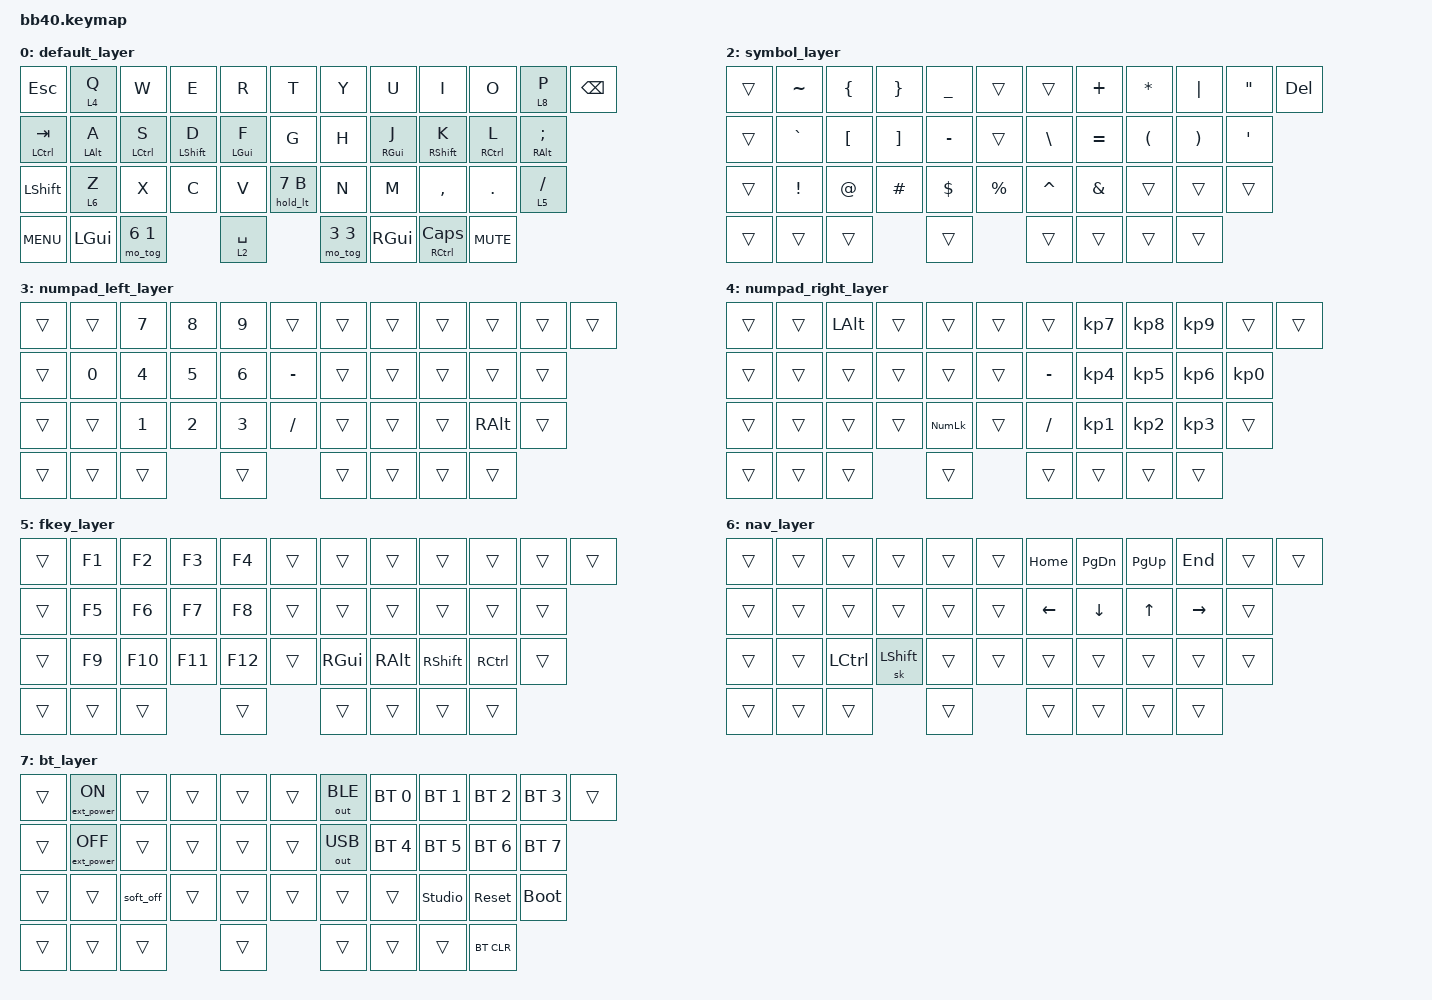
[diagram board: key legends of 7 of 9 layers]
/*
 * Copyright (c) 2025 The ZMK Contributors
 *
 * SPDX-License-Identifier: MIT
 */

#include <behaviors.dtsi>
#include <dt-bindings/zmk/bt.h>
#include <dt-bindings/zmk/ext_power.h>
#include <dt-bindings/zmk/keys.h>
#include <dt-bindings/zmk/outputs.h>

#include "less_constants.h"

#include "less_behaviors.dtsi"
#include "s40nc_combos.dtsi"
#include "less_macros.dtsi"

&encoder {
    status = "okay";
};

/*
&sensors {
    sensors = <&qdec_encoder>;
};
*/

/ {
    chosen { zmk,physical-layout = &full_space_layout; };

    keymap {
        compatible = "zmk,keymap";

        default_layer {
            bindings = <
                &kp ESC        &lt 4 Q     &kp W        &kp E        &kp R        &kp T         &kp Y        &kp U       &kp I           &kp O        &lt 8 P     &kp BSPC
                &mt LCTRL TAB  &mt LALT A  &mt LCTRL S  &mt LSHFT D  &mt LGUI F   &kp G         &kp H        &mt RGUI J  &mt RSHFT K     &mt RCTRL L  &mt RALT SEMI
                &kp LSHFT      &lt 6 Z     &kp X        &kp C        &kp V        &hold_lt 7 B  &kp N        &kp M       &kp COMMA       &kp DOT      &lt 5 FSLH
                &kp C_MENU     &kp LGUI    &mo_tog 6 1               &lt 2 SPACE                &mo_tog 3 3  &kp RGUI    &mt RCTRL CAPS  &kp C_MUTE
            >;
            sensor-bindings = <&inc_dec_kp C_VOL_UP C_VOL_DN>;
        };

        gaming {
            bindings = <
                &trans  &trans  &trans  &trans  &trans  &trans  &trans  &trans  &trans  &trans  &trans   &trans
                &kp TAB  &kp A  &kp S   &kp D   &kp F   &trans  &trans  &kp J   &kp K   &kp L   &kp SEMI
                &trans  &trans  &trans  &trans  &trans  &trans  &trans  &trans  &trans  &trans  &trans
                &trans  &trans  &trans  &trans  &trans  &trans  &trans  &trans  &trans  &trans  &trans
                &trans  &trans  &trans  &trans          &trans                  &trans  &trans  &trans   &trans
            >;
        };

        symbol_layer {
            bindings = <
                &trans  &kp TILDE  &kp LBRC  &kp RBRC  &kp UNDER &trans     &trans     &kp PLUS  &kp STAR  &kp PIPE  &kp DQT  &kp DEL
                &trans  &kp GRAVE  &kp LBKT  &kp RBKT  &kp MINUS &trans     &kp BSLH   &kp EQUAL &kp LPAR  &kp RPAR  &kp SQT
                &trans  &kp EXCL   &kp AT    &kp HASH  &kp DLLR  &kp PRCNT  &kp CARET  &kp AMPS  &trans    &trans    &trans
                &trans  &trans     &trans                        &trans                          &trans    &trans    &trans    &trans
            >;
        };

        numpad_left_layer {
            bindings = <
                &trans  &trans  &kp N7  &kp N8  &kp N9  &trans     &trans  &trans  &trans  &trans    &trans  &trans
                &trans  &kp N0  &kp N4  &kp N5  &kp N6  &kp MINUS  &trans  &trans  &trans  &trans    &trans
                &trans  &trans  &kp N1  &kp N2  &kp N3  &kp FSLH   &trans  &trans  &trans  &kp RALT  &trans
                &trans  &trans  &trans                  &trans                     &trans  &trans    &trans    &trans
            >;
        };

        numpad_right_layer {
            bindings = <
                &trans  &trans  &kp LALT  &trans  &trans      &trans  &trans     &kp KP_N7  &kp KP_N8  &kp KP_N9  &trans     &trans
                &trans  &trans  &trans    &trans  &trans      &trans  &kp MINUS  &kp KP_N4  &kp KP_N5  &kp KP_N6  &kp KP_N0
                &trans  &trans  &trans    &trans  &kp KP_NUM  &trans  &kp FSLH   &kp KP_N1  &kp KP_N2  &kp KP_N3  &trans
                &trans  &trans  &trans                        &trans                        &trans     &trans     &trans    &trans
            >;
        };

        fkey_layer {
            bindings = <
                &trans  &kp F1  &kp F2  &kp F3  &kp F4    &trans  &trans    &trans     &trans     &trans     &trans     &trans
                &trans  &kp F5  &kp F6  &kp F7  &kp F8    &trans  &trans    &trans     &trans     &trans     &trans
                &trans  &kp F9  &kp F10 &kp F11 &kp F12   &trans  &kp RGUI  &kp RALT   &kp RSHFT  &kp RCTRL  &trans
                &trans  &trans  &trans                    &trans                       &trans     &trans     &trans    &trans
            >;
        };

        nav_layer {
            bindings = <
                &trans  &trans    &trans     &trans     &trans  &trans  &kp HOME  &kp PG_DN  &kp PG_UP  &kp END    &trans     &trans
                &trans  &trans    &trans     &trans     &trans  &trans  &kp LEFT  &kp DOWN   &kp UP     &kp RIGHT  &trans
                &trans  &trans    &kp LCTRL  &sk LSHFT  &trans  &trans  &trans    &trans     &trans     &trans     &trans
                &trans  &trans    &trans                        &trans                       &trans     &trans     &trans    &trans
            >;
        };

        bt_layer {
            bindings = <
                &trans  &ext_power EP_ON   &trans     &trans  &trans  &trans  &out OUT_BLE  &bt BT_SEL 0  &bt BT_SEL 1    &bt BT_SEL 2  &bt BT_SEL 3  &trans
                &trans  &ext_power EP_OFF  &trans     &trans  &trans  &trans  &out OUT_USB  &bt BT_SEL 4  &bt BT_SEL 5    &bt BT_SEL 6  &bt BT_SEL 7
                &trans  &trans             &soft_off  &trans  &trans  &trans  &trans        &trans        &studio_unlock  &sys_reset    &bootloader
                &trans  &trans             &trans                     &trans                              &trans          &trans        &trans        &bt BT_CLR
            >;
        };

        etc_layer {
            bindings = <
                &trans  &trans  &kp C_VOL_UP  &trans  &trans  &trans  &trans  &trans  &trans  &trans  &trans  &trans
                &trans  &trans  &kp C_VOL_DN  &trans  &trans  &trans  &trans  &trans  &trans  &trans  &trans
                &trans  &trans  &trans        &trans  &trans  &trans  &trans  &trans  &trans  &trans  &trans
                &trans  &trans  &trans        &trans          &trans                  &trans  &trans  &trans  &trans
            >;
        };
    };
};
